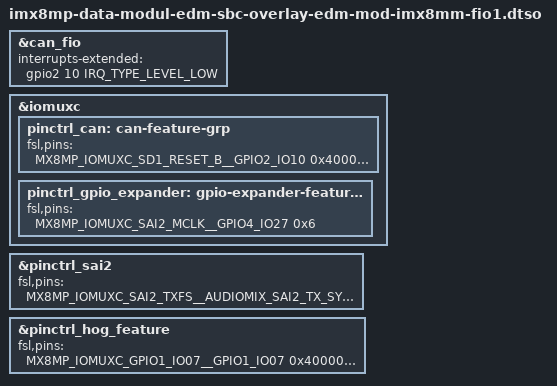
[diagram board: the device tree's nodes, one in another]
// SPDX-License-Identifier: (GPL-2.0+ OR MIT)
/*
 * Copyright 2022-2026 Marek Vasut
 */
/dts-v1/;
/plugin/;

#include "imx8mp-pinfunc.h"
#include "imx8mm-data-modul-edm-sbc-overlay-edm-mod-imx8mm-fio1.dtsi"

&can_fio {
	interrupts-extended = <&gpio2 10 IRQ_TYPE_LEVEL_LOW>;
};

&iomuxc {
	pinctrl_can: can-feature-grp {
		fsl,pins = <
			/* CAN_INT# */
			MX8MP_IOMUXC_SD1_RESET_B__GPIO2_IO10		0x400000d6
		>;
	};

	pinctrl_gpio_expander: gpio-expander-feature-grp {
		fsl,pins = <
			/* GPIO4_IO27 */
			MX8MP_IOMUXC_SAI2_MCLK__GPIO4_IO27		0x6
		>;
	};
};

&pinctrl_sai2 {
	fsl,pins = <
		MX8MP_IOMUXC_SAI2_TXFS__AUDIOMIX_SAI2_TX_SYNC	0xd6
		MX8MP_IOMUXC_SAI2_TXD0__AUDIOMIX_SAI2_TX_DATA00	0xd6
		MX8MP_IOMUXC_SAI2_TXC__AUDIOMIX_SAI2_TX_BCLK	0xd6
	>;
};

&pinctrl_hog_feature {
	fsl,pins = <
		/* GPIO5_IO03 */
		MX8MP_IOMUXC_GPIO1_IO07__GPIO1_IO07		0x40000006
		/* GPIO5_IO04 */
		MX8MP_IOMUXC_GPIO1_IO08__GPIO1_IO08		0x40000006
	>;
};
